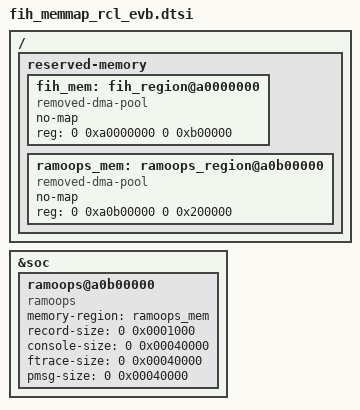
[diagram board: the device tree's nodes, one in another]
/* ref: msm8998.dtsi */

/ {
	reserved-memory {
		fih_mem: fih_region@a0000000 { /* for FIH feature */
			compatible = "removed-dma-pool";
			no-map;
			reg = <0 0xa0000000 0 0xb00000>;
		};
		ramoops_mem: ramoops_region@a0b00000 { /* for ramoops feature */
			compatible = "removed-dma-pool";
			no-map;
			reg = <0 0xa0b00000 0 0x200000>;
		};
	};
};
&soc {
	/* KenTHChen Add for fih_apr driver */
	#include "fih_apr.dtsi"
	/* YL Add for ddr test result info */
	#include "system-ddr-info.dtsi"
	
	ramoops@a0b00000 {
		compatible = "ramoops";
		memory-region = <&ramoops_mem>;
		record-size = <0 0x0001000>;
		console-size = <0 0x00040000>;
		ftrace-size = <0 0x00040000>;
		pmsg-size = <0 0x00040000>;
	};
};
